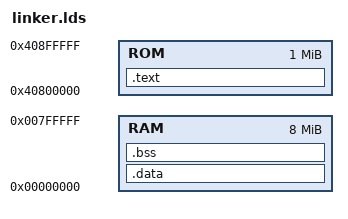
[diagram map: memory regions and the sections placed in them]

ENTRY(_start)

MEMORY
{
        ROM : ORIGIN = 0x40800000, LENGTH = 1M
        RAM : ORIGIN = 0x00000000, LENGTH = 8M
}

SECTIONS
{
        /**********************************************************************
         *                                                                    *
         **********************************************************************/
        .text :
        {
                _stext = .;
                KEEP(*(.vectors))
                *(.startup)
                *(.text)
                *(.text.*)
                *(.rodata)
                *(.rodata.*)
                . = ALIGN(0x10);
                _etext = .;
        } > ROM
        /**********************************************************************
         *                                                                    *
         **********************************************************************/
        .data : AT(_etext)
        {
                _sdata = .;
                *(.data)
                *(.data.*)
                . = ALIGN(0x10);
                _edata = .;
        } > RAM
        /**********************************************************************
         *                                                                    *
         **********************************************************************/
        .bss ADDR(.data) + SIZEOF(.data) (NOLOAD) :
        {
                _sbss = .;
                *(.bss)
                *(.bss.*)
                *(COMMON)
                . = ALIGN(0x10);
                _ebss = .;
        } > RAM
        /**********************************************************************
         *                                                                    *
         **********************************************************************/
        .debug_info     0 : { *(.debug_info) }
        .debug_abbrev   0 : { *(.debug_abbrev) }
        .debug_aranges  0 : { *(.debug_aranges) }
        .debug_frame    0 : { *(.debug_frame) }
        .debug_line     0 : { *(.debug_line) }
        .debug_line_str 0 : { *(.debug_line_str) }
        .debug_loclists 0 : { *(.debug_loclists) }
        .debug_macro    0 : { *(.debug_macro) }
        .debug_names    0 : { *(.debug_names) }
        .debug_rnglists 0 : { *(.debug_rnglists) }
        .debug_str      0 : { *(.debug_str) }
        /**********************************************************************
         *                                                                    *
         **********************************************************************/
        /DISCARD/ :
        {
                *(*)
        }
}

